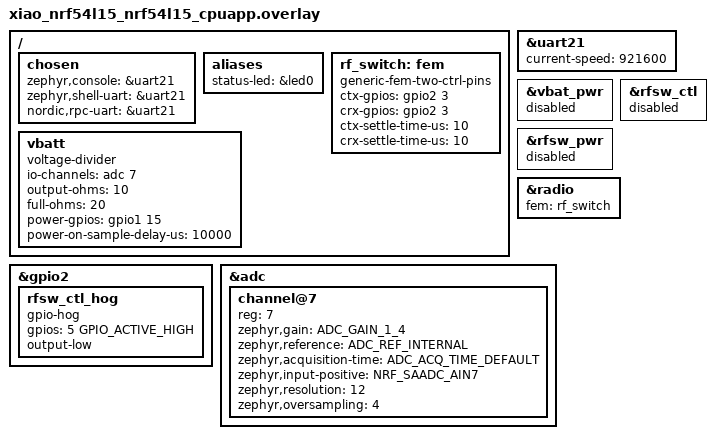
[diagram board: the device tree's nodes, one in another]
/ {
    chosen {
        zephyr,console = &uart21;
        zephyr,shell-uart = &uart21;
        nordic,rpc-uart = &uart21;
    };

    aliases {
        status-led = &led0;
    };
};

&uart21 {
    current-speed = <921600>;
};

&vbat_pwr {
    status = "disabled";
};

&rfsw_pwr {
    status = "disabled";
};

&rfsw_ctl {
    status = "disabled";
};

// This selects the onboard antenna.
&gpio2 {
    rfsw_ctl_hog {
        gpio-hog;
        gpios = <5 GPIO_ACTIVE_HIGH>;
        output-low;
    };
};

// Only power the RF switch when needed.
/ {
    rf_switch: fem {
        compatible = "generic-fem-two-ctrl-pins";
        ctx-gpios = <&gpio2 3 GPIO_ACTIVE_HIGH>;
        crx-gpios = <&gpio2 3 GPIO_ACTIVE_HIGH>;
        ctx-settle-time-us = <10>;
        crx-settle-time-us = <10>;
    };
};

&radio {
    fem = <&rf_switch>;
};

#include <zephyr/dt-bindings/adc/adc.h>
#include <zephyr/dt-bindings/adc/nrf-saadc.h>

/ {
    vbatt {
        compatible = "voltage-divider";
        io-channels = <&adc 7>;
        output-ohms = <10>;
        full-ohms = <20>;
        power-gpios = <&gpio1 15 GPIO_ACTIVE_HIGH>;
        power-on-sample-delay-us = <10000>;
    };
};

&adc {
    #address-cells = <1>;
    #size-cells = <0>;

    channel@7 {
        reg = <7>;
        zephyr,gain = "ADC_GAIN_1_4";
        zephyr,reference = "ADC_REF_INTERNAL";
        zephyr,acquisition-time = <ADC_ACQ_TIME_DEFAULT>;
        zephyr,input-positive = <NRF_SAADC_AIN7>;
        zephyr,resolution = <12>;
        zephyr,oversampling = <4>;
    };
};
